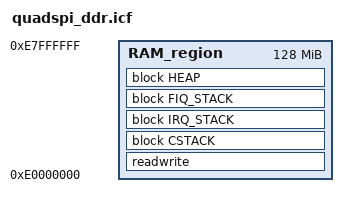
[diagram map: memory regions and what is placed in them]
/*###ICF### Section handled by ICF editor, don't touch! ****/
/*-Editor annotation file-*/
/* IcfEditorFile="$TOOLKIT_DIR$\config\ide\IcfEditor\a_v1_0.xml" */
/*-Specials-*/
define symbol __ICFEDIT_intvec_start__ = 0xe0000800;
/*-Memory Regions-*/
define symbol __ICFEDIT_region_ROM_start__   = 0x0;
define symbol __ICFEDIT_region_ROM_end__     = 0x0;
define symbol __ICFEDIT_region_RAM_start__   = 0xe0000000;
define symbol __ICFEDIT_region_RAM_end__     = 0xe7ffffff;
/*-Sizes-*/
define symbol __ICFEDIT_size_cstack__   = 0x1000;
define symbol __ICFEDIT_size_svcstack__ = 0x40;
define symbol __ICFEDIT_size_irqstack__ = 0x100;
define symbol __ICFEDIT_size_fiqstack__ = 0x40;
define symbol __ICFEDIT_size_undstack__ = 0x40;
define symbol __ICFEDIT_size_abtstack__ = 0x40;
define symbol __ICFEDIT_size_heap__     = 0x2000;
/**** End of ICF editor section. ###ICF###*/

define exported symbol __intvec_start = __ICFEDIT_intvec_start__;

define memory mem with size = 4G;
define region ROM_region   = mem:[from __ICFEDIT_region_ROM_start__   to __ICFEDIT_region_ROM_end__];
define region RAM_region   = mem:[from __ICFEDIT_region_RAM_start__   to __ICFEDIT_region_RAM_end__];

define block CSTACK    with alignment = 8, size = __ICFEDIT_size_cstack__   { };
define block IRQ_STACK with alignment = 8, size = __ICFEDIT_size_irqstack__ { };
define block FIQ_STACK with alignment = 8, size = __ICFEDIT_size_fiqstack__ { };
define block HEAP      with alignment = 8, size = __ICFEDIT_size_heap__     { };

define block Conf_Data with alignment = 4, size = 0x400 {section .conf};
define block VTV_Data  with alignment = 4, size = 0x400 {section .ivt};

do not initialize   { section .noinit };

place in RAM_region { block app_image with fixed order {block Conf_Data, block VTV_Data, readonly section .intvec, readonly}};
place in RAM_region { readwrite,
                      block CSTACK, block IRQ_STACK, block FIQ_STACK, block HEAP };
